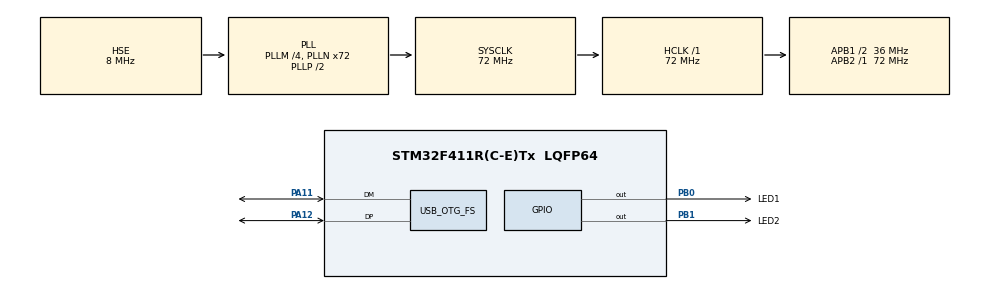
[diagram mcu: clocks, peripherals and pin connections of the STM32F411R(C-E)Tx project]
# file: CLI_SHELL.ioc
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Mcu.Family=STM32F4
Mcu.Name=STM32F411R(C-E)Tx
Mcu.Package=LQFP64
NVIC.OTG_FS_IRQn=true\:0\:0\:false\:false\:true\:false\:true
NVIC.PriorityGroup=NVIC_PRIORITYGROUP_4
PA11.Mode=Device_Only
PA11.Signal=USB_OTG_FS_DM
PA12.Mode=Device_Only
PA12.Signal=USB_OTG_FS_DP
PA13.Mode=JTAG_4_pins
PA13.Signal=SYS_JTMS-SWDIO
PA14.Mode=JTAG_4_pins
PA14.Signal=SYS_JTCK-SWCLK
PA15.Mode=JTAG_4_pins
PA15.Signal=SYS_JTDI
PB0.GPIO_Label=LED1
PB0.Signal=GPIO_Output
PB1.GPIO_Label=LED2
PB1.Signal=GPIO_Output
PB3.Mode=JTAG_4_pins
PB3.Signal=SYS_JTDO-SWO
PH0\ -\ OSC_IN.Mode=HSE-External-Oscillator
PH0\ -\ OSC_IN.Signal=RCC_OSC_IN
PH1\ -\ OSC_OUT.Mode=HSE-External-Oscillator
PH1\ -\ OSC_OUT.Signal=RCC_OSC_OUT
ProjectManager.HeapSize=0x400
ProjectManager.StackSize=0x800
ProjectManager.TargetToolchain=STM32CubeIDE
RCC.48MHZClocksFreq_Value=48000000
RCC.AHBFreq_Value=72000000
RCC.APB1CLKDivider=RCC_HCLK_DIV2
RCC.APB1Freq_Value=36000000
RCC.APB1TimFreq_Value=72000000
RCC.APB2Freq_Value=72000000
RCC.APB2TimFreq_Value=72000000
RCC.CortexFreq_Value=72000000
RCC.HCLKFreq_Value=72000000
RCC.HSE_VALUE=8000000
RCC.HSI_VALUE=16000000
RCC.LSE_VALUE=32768
RCC.PLLM=4
RCC.PLLN=72
RCC.PLLQ=3
RCC.SYSCLKFreq_VALUE=72000000
RCC.SYSCLKSource=RCC_SYSCLKSOURCE_PLLCLK
RCC.VCOOutputFreq_Value=144000000
USB_DEVICE.APP_RX_DATA_SIZE=2048
USB_DEVICE.APP_TX_DATA_SIZE=2048
USB_DEVICE.CLASS_NAME_FS=CDC
USB_DEVICE.USBD_DEBUG_LEVEL=3
USB_DEVICE.VirtualMode=Cdc
USB_DEVICE.VirtualModeFS=Cdc_FS
USB_OTG_FS.VirtualMode=Device_Only
VP_USB_DEVICE_VS_USB_DEVICE_CDC_FS.Mode=CDC_FS
board=custom

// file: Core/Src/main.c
/* USER CODE BEGIN Header */
/**
  ******************************************************************************
  * @file           : main.c
  * @brief          : Main program body
  ******************************************************************************
  * @attention
  *
  * <h2><center>&copy; Copyright (c) 2020 STMicroelectronics.
  * All rights reserved.</center></h2>
  *
  * This software component is licensed by ST under BSD 3-Clause license,
  * the "License"; You may not use this file except in compliance with the
  * License. You may obtain a copy of the License at:
  *                        opensource.org/licenses/BSD-3-Clause
  *
  ******************************************************************************
  */
/* USER CODE END Header */

#include "main.h"
#include "usb_device.h"

/* USER CODE BEGIN Includes */
#include "CLI_SHELL.h"
/* USER CODE END Includes */

void SystemClock_Config(void);
static void MX_GPIO_Init(void);

int main(void)
{

  /* MCU Configuration--------------------------------------------------------*/

  /* Reset of all peripherals, Initializes the Flash interface and the Systick. */
  HAL_Init();

  /* Configure the system clock */
  SystemClock_Config();

  /* Initialize all configured peripherals */
  MX_GPIO_Init();
  MX_USB_DEVICE_Init();

  /* Infinite loop */
  /* USER CODE BEGIN WHILE */
  while (1)
  {

	  checkShellStatus();

    /* USER CODE END WHILE */

  }
}

void SystemClock_Config(void)
{
  RCC_OscInitTypeDef RCC_OscInitStruct = {0};
  RCC_ClkInitTypeDef RCC_ClkInitStruct = {0};

  /** Configure the main internal regulator output voltage
  */
  __HAL_RCC_PWR_CLK_ENABLE();
  __HAL_PWR_VOLTAGESCALING_CONFIG(PWR_REGULATOR_VOLTAGE_SCALE1);
  /** Initializes the CPU, AHB and APB busses clocks
  */
  RCC_OscInitStruct.OscillatorType = RCC_OSCILLATORTYPE_HSE;
  RCC_OscInitStruct.HSEState = RCC_HSE_ON;
  RCC_OscInitStruct.PLL.PLLState = RCC_PLL_ON;
  RCC_OscInitStruct.PLL.PLLSource = RCC_PLLSOURCE_HSE;
  RCC_OscInitStruct.PLL.PLLM = 4;
  RCC_OscInitStruct.PLL.PLLN = 72;
  RCC_OscInitStruct.PLL.PLLP = RCC_PLLP_DIV2;
  RCC_OscInitStruct.PLL.PLLQ = 3;
  if (HAL_RCC_OscConfig(&RCC_OscInitStruct) != HAL_OK)
  {
    Error_Handler();
  }
  /** Initializes the CPU, AHB and APB busses clocks
  */
  RCC_ClkInitStruct.ClockType = RCC_CLOCKTYPE_HCLK|RCC_CLOCKTYPE_SYSCLK
                              |RCC_CLOCKTYPE_PCLK1|RCC_CLOCKTYPE_PCLK2;
  RCC_ClkInitStruct.SYSCLKSource = RCC_SYSCLKSOURCE_PLLCLK;
  RCC_ClkInitStruct.AHBCLKDivider = RCC_SYSCLK_DIV1;
  RCC_ClkInitStruct.APB1CLKDivider = RCC_HCLK_DIV2;
  RCC_ClkInitStruct.APB2CLKDivider = RCC_HCLK_DIV1;

  if (HAL_RCC_ClockConfig(&RCC_ClkInitStruct, FLASH_LATENCY_2) != HAL_OK)
  {
    Error_Handler();
  }
}

static void MX_GPIO_Init(void)
{
  GPIO_InitTypeDef GPIO_InitStruct = {0};

  /* GPIO Ports Clock Enable */
  __HAL_RCC_GPIOH_CLK_ENABLE();
  __HAL_RCC_GPIOB_CLK_ENABLE();
  __HAL_RCC_GPIOA_CLK_ENABLE();

  /*Configure GPIO pin Output Level */
  HAL_GPIO_WritePin(GPIOB, LED1_Pin|LED2_Pin, GPIO_PIN_RESET);

  /*Configure GPIO pins : LED1_Pin LED2_Pin */
  GPIO_InitStruct.Pin = LED1_Pin|LED2_Pin;
  GPIO_InitStruct.Mode = GPIO_MODE_OUTPUT_PP;
  GPIO_InitStruct.Pull = GPIO_NOPULL;
  GPIO_InitStruct.Speed = GPIO_SPEED_FREQ_LOW;
  HAL_GPIO_Init(GPIOB, &GPIO_InitStruct);

}

void Error_Handler(void)
{
}

/************************ (C) COPYRIGHT STMicroelectronics *****END OF FILE****/
